# STM32U3C5 register map
File version: 1.0
CPU: CM33 r0p1, little endian, MPU, FPU, 4 interrupt priority bits
Registers are 32-bit, read-write, reset 0x0 unless marked. A register's access mark holds for its fields unless they carry their own. Offsets are from the block's base; [hi:lo] are bit positions; {n}, {i} and the like mark numbered series.

## PWR — PWR register block
Base 0x40030800
Same registers: SEC_PWR 0x50030800
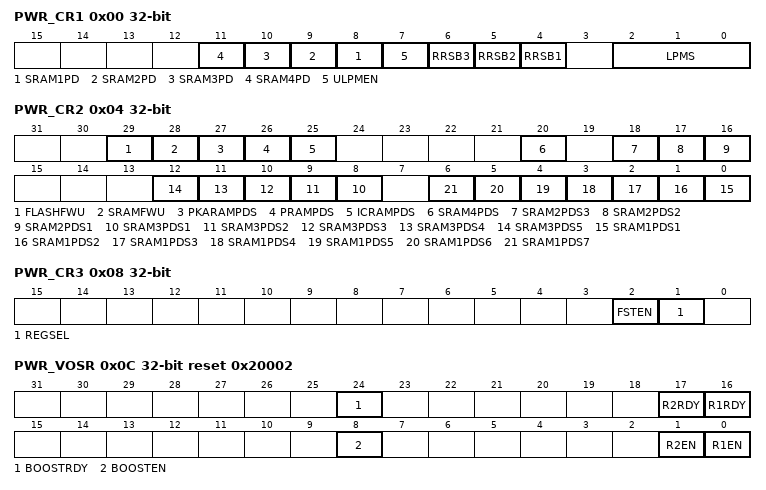
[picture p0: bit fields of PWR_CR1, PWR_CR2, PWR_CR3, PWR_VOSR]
0x00 PWR_CR1
  [n+7] SRAM{n}PD (n=1..4) — SRAM{n} power down
    0=SRAM{n} powered on; 1=SRAM{n} powered off
  [7] ULPMEN — BOR0 ultra-low power mode
    0=BOR level 0 operating in continuous (normal) mode in Standby mode; 1=BOR level 0 operating in discontinuous (ultra-low power) mode in Standby mode
  [6] RRSB3 — SRAM2 page 3 retention in Standby mode
    0=SRAM2 page3 content not retained in Standby mode; 1=SRAM2 page3 content retained in Standby mode
  [5] RRSB2 — SRAM2 page 2 retention in Standby mode
    0=SRAM2 page2 content not retained in Standby mode; 1=SRAM2 page2 content retained in Standby mode
  [4] RRSB1 — SRAM2 page 1 retention in Standby mode
    0=SRAM2 page1 content not retained in Standby mode; 1=SRAM2 page1 content retained in Standby mode
  [2:0] LPMS — Low-power mode selection
    {v}=Stop {v} mode (v=0..3); 4=Standby mode; 5=Standby mode; 6=Shutdown mode; 7=Shutdown mode
0x04 PWR_CR2 — PWR control register 2
  [29] FLASHFWU — Flash memory fast wake-up from Stop 0 and Stop 1 modes
    0=Flash memory enters low-power mode in Stop 0 and Stop 1 modes (lower-power consumption); 1=Flash memory remains in normal mode in Stop 0 and Stop 1 modes (faster wake-up time)
  [28] SRAMFWU — SRAM fast wake-up from Stop 0 and Stop 1 modes
    0=SRAMs enter low-power mode in Stop 0 and Stop 1 modes (source biasing for lower-power consumption); 1=SRAMs remain in normal mode in Stop 0 and Stop 1 modes (higher consumption but no SRAM wake-up time)
  [27] PKARAMPDS — PKA SRAM power-down in Stop1, Stop2, and Stop3 modes
    0=PKA SRAM content retained in Stop modes; 1=PKA SRAM content lost in Stop modes
  [26] PRAMPDS — FDCAN and USB SRAM power-down in Stop1, Stop2, and Stop3 modes
    0=FDCAN and USB SRAM content retained in Stop modes; 1=FDCAN and USB SRAM content lost in Stop modes
  [25] ICRAMPDS — ICACHE SRAM power-down in Stop1, Stop2, and Stop3 modes
    0=ICACHE SRAM content retained in Stop modes; 1=ICACHE SRAM content lost in Stop modes
  [20] SRAM4PDS — SRAM4 power-down in Stop1, Stop2, and Stop3 modes
    0=SRAM4 content retained in Stop modes; 1=SRAM4 content lost in Stop modes
  [18] SRAM2PDS3 — SRAM2 page 3 (8 Kbytes) power-down in Stop1, Stop2, and Stop3 modes
    0=SRAM2 page 3 content retained in Stop modes; 1=SRAM2 page 3 content lost in Stop modes
  [17] SRAM2PDS2 — SRAM2 page 2 (24 Kbytes) power-down in Stop1, Stop2, and Stop3 modes
    0=SRAM2 page 2 content retained in Stop modes; 1=SRAM2 page 2 content lost in Stop modes
  [16] SRAM2PDS1 — SRAM2 page 1 (32 Kbytes) power-down in Stop1, Stop2, and Stop3 modes
    0=SRAM2 page 1 content retained in Stop modes; 1=SRAM2 page 1 content lost in Stop modes
  [n+7] SRAM3PDS{n} (n=1..5) — SRAM3 page i power-down in Stop1, Stop2, and Stop3 modes
    0=SRAM3 page i content retained in Stop modes; 1=SRAM3 page i content lost in Stop modes
  [n-1] SRAM1PDS{n} (n=1..7) — SRAM1 page i power-down in Stop1, Stop2, and Stop3 modes (i=7to1)
    0=SRAM1 page i content retained in Stop modes; 1=SRAM1 page i content lost in Stop modes
0x08 PWR_CR3 — PWR control register 3
  [2] FSTEN — Fast soft start
    0=LDO/SMPS fast startup disabled (limited inrush current); 1=LDO/SMPS fast startup enabled
  [1] REGSEL — Regulator selection
    0=LDO selected; 1=SMPS selected
0x0C PWR_VOSR reset 0x20002 — PWR voltage scaling register
  [24] BOOSTRDY ro — EPOD booster ready
    0=Power booster not ready; 1=Power booster ready
  [17] R2RDY ro — Ready bit for Vless thansub>COREless than/sub> voltage range 2 selection
    0=Range 2 not ready: voltage level less than VOS range 2 level; 1=Range 2 ready: voltage level greater or equal VOS range 2 level
  [16] R1RDY ro — Ready bit for Vless thansub>COREless than/sub> voltage range 1 selection
    0=Range 1 not ready: voltage level less than VOS range 1 level; 1=Range 1 ready: voltage level greater or equal VOS range 1 level
  [8] BOOSTEN — EPOD booster enable
    0=Booster disabled; 1=Booster enabled
  [1] R2EN — Voltage scaling range 2 selection
    0=Voltage scaling range 2 disabled; 1=Voltage scaling range 2 enabled
  [0] R1EN — Voltage scaling range 1 selection
    0=Voltage scaling range 1 disabled; 1=Voltage scaling range 1 enabled
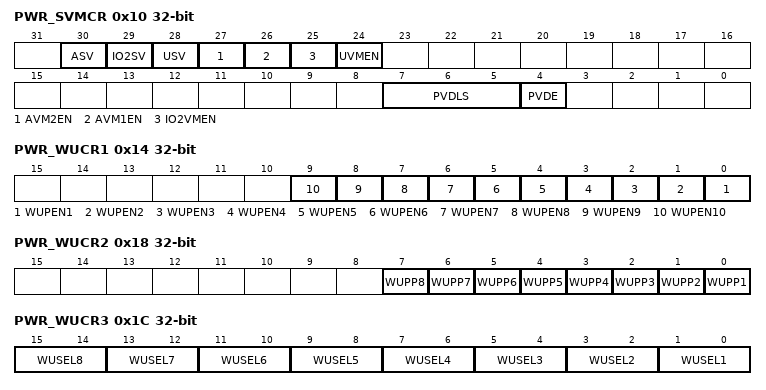
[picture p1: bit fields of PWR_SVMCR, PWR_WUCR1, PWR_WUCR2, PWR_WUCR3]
0x10 PWR_SVMCR — PWR supply voltage monitoring control register
  [30] ASV — Vless thansub>DDAless than/sub> independent analog supply valid
    0=Vless thansub>DDAless than/sub> not present: logical and electrical isolation is applied to ignore this supply; 1=Vless thansub>DDAless than/sub> valid
  [29] IO2SV — Vless thansub>DDIO2less than/sub> independent I/O supply valid
    0=Vless thansub>DDIO2less than/sub> not present: logical and electrical isolation is applied to ignore this supply; 1=Vless thansub>DDIO2less than/sub> valid
  [28] USV — Vless thansub>DDUSBless than/sub> independent USB supply valid
    0=Vless thansub>DDUSBless than/sub> not present: logical and electrical isolation is applied to ignore this supply; 1=Vless thansub>DDUSBless than/sub> valid
  [27] AVM2EN — Vless thansub>DDAless than/sub> independent analog supply voltage monitor 2 enable (1.
    0=Vless thansub>DDAless than/sub> voltage monitor 2 disabled; 1=Vless thansub>DDAless than/sub> voltage monitor 2 enabled
  [26] AVM1EN — Vless thansub>DDAless than/sub> independent analog supply voltage monitor 1 enable (1.
    0=Vless thansub>DDAless than/sub> voltage monitor 1 disabled; 1=Vless thansub>DDAless than/sub> voltage monitor 1 enabled
  [25] IO2VMEN — Vless thansub>DDIO2less than/sub> independent I/O voltage monitor enable
    0=Vless thansub>DDIO2less than/sub> voltage monitor disabled; 1=Vless thansub>DDIO2less than/sub> voltage monitor enabled
  [24] UVMEN — Vless thansub>DDUSBless than/sub>independent USB voltage monitor enable
    0=Vless thansub>DDUSBless than/sub> voltage monitor disabled; 1=Vless thansub>DDUSBless than/sub> voltage monitor enabled
  [7:5] PVDLS — Programmable voltage detector (PVD) level selection
    {v}=Vless thansub>PVD{v}less than/sub> around 2 (v=0..6); 7=External input analog voltage PVD_IN (compared internally to VREFINT)
  [4] PVDE — Programmable voltage detector enable
    0=PVD disabled; 1=PVD enabled
0x14 PWR_WUCR1 — PWR wake-up control register 1
  [all] fields
    0=Wake-up line WKUPi disabled; 1=Wake-up line WKUPi enabled
  [n-1] WUPEN{n} (n=1..10) — Wake-up line WKUPi enable
0x18 PWR_WUCR2 — PWR wake-up control register 2
  [all] fields
    0=Detection on high level (rising edge); 1=Detection on low level (falling edge)
  [n-1] WUPP{n} (n=1..8) — Wake-up line WKUP8 polarity
0x1C PWR_WUCR3 — PWR wake-up control register 3
  [all] fields
    {v}=WKUPi_{v} (v=0..3)
  [2n-1:2n-2] WUSEL{n} (n=1..8) — Wake-up line WKUPi selection
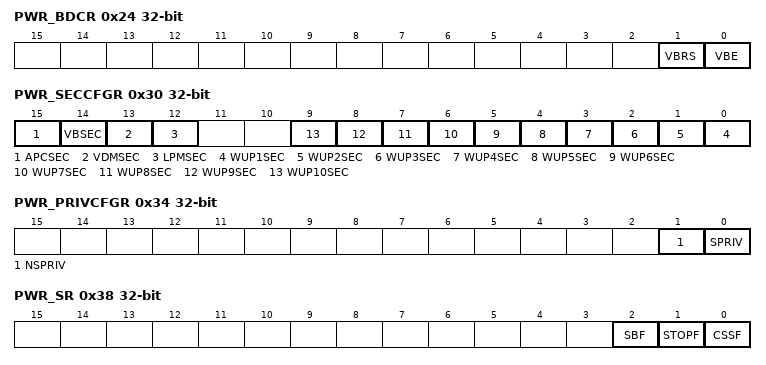
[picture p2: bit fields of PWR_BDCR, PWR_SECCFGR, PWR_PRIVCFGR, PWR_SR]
0x24 PWR_BDCR — PWR backup domain control register
  [1] VBRS — Vless thansub>BATless than/sub> charging resistor selection
    0=Vless thansub>BATless than/sub> charged through a 5 kohm resistor; 1=Vless thansub>BATless than/sub> charged through a 1
  [0] VBE — Vless thansub>BATless than/sub> charging enable
    0=Vless thansub>BATless than/sub> battery charging disabled; 1=Vless thansub>BATless than/sub> battery charging enabled
0x28 PWR_DBPR — PWR disable backup domain register
  [0] DBP — Disable backup domain write protection
    0=Write access to backup domain disabled; 1=Write access to backup domain enabled
0x30 PWR_SECCFGR — PWR security configuration register
  [15] APCSEC — Pull-up/pull-down secure protection
    0=PWR_APCR can be read and written with secure or nonsecure access; 1=PWR_APCR can be read and written only with secure access
  [14] VBSEC — Backup domain secure protection
    0=PWR_BDCR and PWR_DBPR can be read and written with secure or nonsecure access; 1=PWR_BDCR and PWR_DBPR can be read and written only with secure access
  [13] VDMSEC — Voltage detection and monitoring secure protection
    0=PWR_SVMCR and PWR_CR3 can be read and written with secure or nonsecure access; 1=PWR_SVMCR and PWR_CR3 can be read and written only with secure access
  [12] LPMSEC — Low-power mode secure protection
    0=PWR_CR1, PWR_CR2, and CSSF bit in the PWR_SR can be read and written with secure or nonsecure access; 1=PWR_CR1, PWR_CR2, and CSSF bit in the PWR_SR can be read and written only with secure access
  [n-1] WUP{n}SEC (n=1..10) — WUPi secure protection
    0=Bits related to the WKUPi line in PWR_WUCR1, PWR_WUCR2, PWR_WUCR3, and PWR_WUSCR can be read and written with secure or nonsecure access; 1=Bits related to the WKUPi line in PWR_WUCR1, PWR_WUCR2, PWR_WUCR3, and PWR_WUSCR can be read and written only with secure access
0x34 PWR_PRIVCFGR — PWR privilege control register
  [1] NSPRIV — PWR nonsecure function privilege configuration
    0=Read and write to PWR nonsecure functions can be done by privileged or unprivileged access; 1=Read and write to PWR nonsecure functions can be done by privileged access only
  [0] SPRIV — PWR secure function privilege configuration
    0=Read and write to PWR secure functions can be done by privileged or unprivileged access; 1=Read and write to PWR secure functions can be done by privileged access only
0x38 PWR_SR — PWR status register
  [2] SBF ro — Standby flag
    0=The device did not enter Standby mode; 1=The device entered Standby mode
  [1] STOPF ro — Stop flag
    0=The device did not enter any Stop mode; 1=The device entered a Stop mode
  [0] CSSF wo — Clear Stop and Standby flags
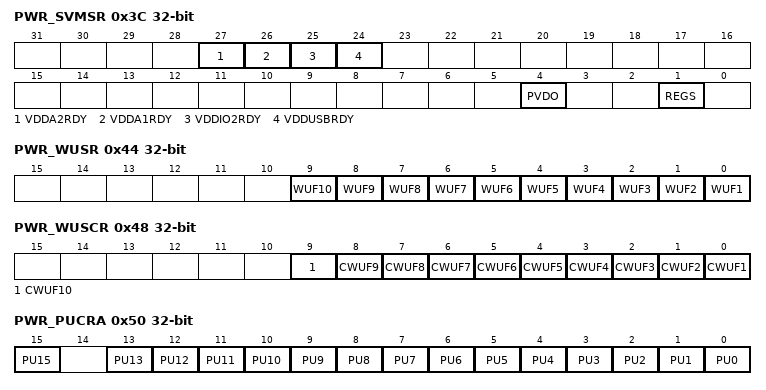
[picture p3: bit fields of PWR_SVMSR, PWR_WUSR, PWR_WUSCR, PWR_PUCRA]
0x3C PWR_SVMSR ro — PWR supply voltage monitoring status register
  [27] VDDA2RDY — Vless thansub>DDAless than/sub> ready versus 1.
    0=Vless thansub>DDAless than/sub> is below the threshold of the Vless thansub>DDAless than/sub> voltage monitor 2 (around 1; 1=Vless thansub>DDAless than/sub> is equal or above the threshold of the Vless thansub>DDAless than/sub> voltage monitor 2 (around 1
  [26] VDDA1RDY — Vless thansub>DDAless than/sub> ready versus 1.
    0=Vless thansub>DDAless than/sub> is below the threshold of the Vless thansub>DDAless than/sub> voltage monitor 1 (around 1; 1=Vless thansub>DDAless than/sub> is equal or above the threshold of the Vless thansub>DDAless than/sub> voltage monitor 1 (around 1
  [25] VDDIO2RDY — Vless thansub>DDIO2 less than/sub>ready
    0=Vless thansub>DDIO2less than/sub> is below the threshold of the Vless thansub>DDIO2less than/sub> voltage monitor; 1=Vless thansub>DDIO2less than/sub> is equal or above the threshold of the Vless thansub>DDIO2less than/sub> voltage monitor
  [24] VDDUSBRDY — Vless thansub>DDUSBless than/sub> ready
    0=Vless thansub>DDUSBless than/sub> is below the threshold of the Vless thansub>DDUSBless than/sub> voltage monitor; 1=Vless thansub>DDUSBless than/sub> is equal or above the threshold of the Vless thansub>DDUSBless than/sub> voltage monitor
  [4] PVDO — Programmable voltage detector output
    0=Vless thansub>DDless than/sub> is equal or above the PVD threshold selected by PVDLS[2:0]; 1=Vless thansub>DDless than/sub> is below the PVD threshold selected by PVDLS[2:0]
  [1] REGS — Regulator selection
    0=LDO selected; 1=SMPS selected
0x44 PWR_WUSR ro — PWR wake-up status register
  [n-1] WUF{n} (n=1..10) — Wake-up flag i
0x48 PWR_WUSCR wo — PWR wake-up status clear register
  [n-1] CWUF{n} (n=1..10) — Wake-up flag i clear
0x4C PWR_APCR — PWR apply pull configuration register
  [0] APC — Apply pull-up and pull-down configuration
0x50 PWR_PUCRA — PWR port A pull-up control register
  [15] PU15 — Port A pull-up bit 15
  [n] PU{n} (n=0..13) — Port A pull-up bit y
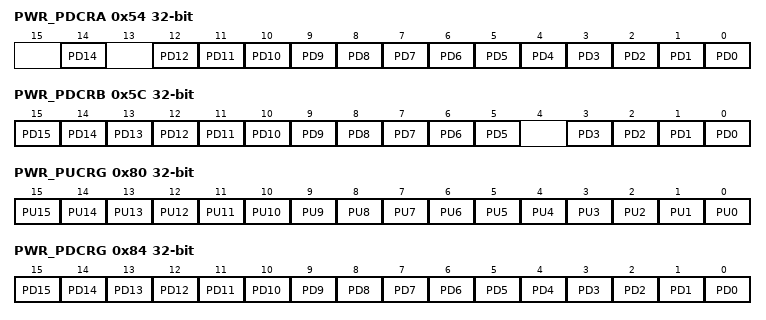
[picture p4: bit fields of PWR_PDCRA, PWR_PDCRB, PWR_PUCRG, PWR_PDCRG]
0x54 PWR_PDCRA — PWR port A pull-down control register
  [14] PD14 — Port A pull-down bit 14
  [n] PD{n} (n=0..12) — Port A pull-down bit y
0x5C PWR_PDCRB — PWR port B pull-down control register
  [n] PD{n} (n=5..15) — Port B pull-down bit y
  [n] PD{n} (n=0..3) — Port B pull-down bit y
0x80 PWR_PUCRG — PWR port G pull-up control register
  [n] PU{n} (n=0..15) — Port G pull-up bit y
0x84 PWR_PDCRG — PWR port G pull-down control register
  [n] PD{n} (n=0..15) — Port G pull-down bit y
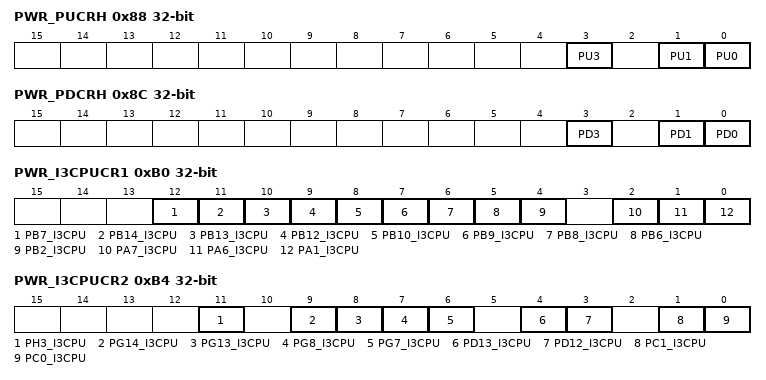
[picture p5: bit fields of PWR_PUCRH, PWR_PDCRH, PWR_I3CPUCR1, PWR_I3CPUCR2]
0x88 PWR_PUCRH — PWR port H pull-up control register
  [3] PU3 — Port H pull-up bit 3
  [1] PU1 — Port H pull-up bit y
  [0] PU0 — Port H pull-up bit y
0x8C PWR_PDCRH — PWR port H pull-down control register
  [3] PD3 — Port H pull-down bit 3
  [1] PD1 — Port H pull-down bit y
  [0] PD0 — Port H pull-down bit y
0xB0 PWR_I3CPUCR1 — PWR I3C pull-up control register 1
  [12] PB7_I3CPU — Port B pin 7 I3C pull-up
  [11] PB14_I3CPU — Port B pin x I3C pull-up
  [10] PB13_I3CPU — Port B pin x I3C pull-up
  [9] PB12_I3CPU — Port B pin x I3C pull-up
  [8] PB10_I3CPU — Port B pin y I3C pull-up
  [7] PB9_I3CPU — Port B pin y I3C pull-up
  [6] PB8_I3CPU — Port B pin y I3C pull-up
  [5] PB6_I3CPU — Port B pin 6 I3C pull-up
  [4] PB2_I3CPU — Port B pin 2 I3C pull-up
  [2] PA7_I3CPU — Port A pin y I3C pull-up
  [1] PA6_I3CPU — Port A pin y I3C pull-up
  [0] PA1_I3CPU — Port A pin 1 I3C pull-up
0xB4 PWR_I3CPUCR2 — PWR I3C pull-up control register 2
  [11] PH3_I3CPU — Port H pin 3 I3C pull-up
  [9] PG14_I3CPU — Port G pin x I3C pull-up
  [8] PG13_I3CPU — Port G pin x I3C pull-up
  [7] PG8_I3CPU — Port G pin y I3C pull-up
  [6] PG7_I3CPU — Port G pin y I3C pull-up
  [4] PD13_I3CPU — Port D pin y I3C pull-up
  [3] PD12_I3CPU — Port D pin y I3C pull-up
  [1] PC1_I3CPU — Port C pin 1 I3C pull-up
  [0] PC0_I3CPU — Port C pin 1 I3C pull-up
